# G32F002 register map
File version: 1.0
CPU: CM0PLUS r0p1, little endian, no MPU, no FPU, 4 interrupt priority bits
Registers are 32-bit, read-write, reset 0x0 unless marked. A register's access mark holds for its fields unless they carry their own. Offsets are from the block's base; [hi:lo] are bit positions; {n}, {i} and the like mark numbered series.

## ATMR — Advance timer
Base 0x40000000
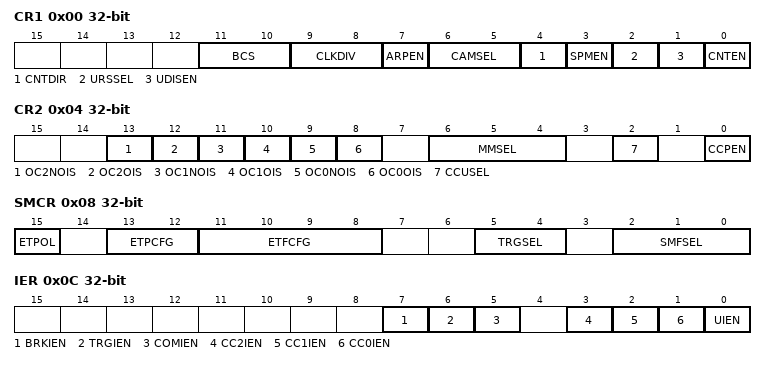
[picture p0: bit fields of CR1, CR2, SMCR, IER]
0x00 CR1 — control register 1
  [11:10] BCS — BRK Source Selection
  [9:8] CLKDIV — Clock division
  [7] ARPEN — Auto-reload preload enable
  [6:5] CAMSEL — Center-aligned mode selection
  [4] CNTDIR — Direction
  [3] SPMEN — One-pulse mode
  [2] URSSEL — Update request source
  [1] UDISEN — Update disable
  [0] CNTEN — Counter enable
0x04 CR2 — control register 2
  [13] OC2NOIS — Output Idle state 2
  [12] OC2OIS — Output Idle state 2
  [11] OC1NOIS — Output Idle state 1
  [10] OC1OIS — Output Idle state 1
  [9] OC0NOIS — Output Idle state 0
  [8] OC0OIS — Output Idle state 0
  [6:4] MMSEL — Master mode selection
  [2] CCUSEL — Capture/compare control update selection
  [0] CCPEN — Capture/compare preloaded control
0x08 SMCR — slave mode control register
  [15] ETPOL — External trigger polarity
  [13:12] ETPCFG — External trigger prescaler
  [11:8] ETFCFG — External trigger filter
  [5:4] TRGSEL — Trigger selection
  [2:0] SMFSEL — Slave mode selection
0x0C IER — Interrupt enable register
  [7] BRKIEN — Break interrupt enable
  [6] TRGIEN — Trigger interrupt enable
  [5] COMIEN — COM interrupt enable
  [3] CC2IEN — Capture/Compare 2 interrupt enable
  [2] CC1IEN — Capture/Compare 1 interrupt enable
  [1] CC0IEN — Capture/Compare 0 interrupt enable
  [0] UIEN — Update interrupt enable
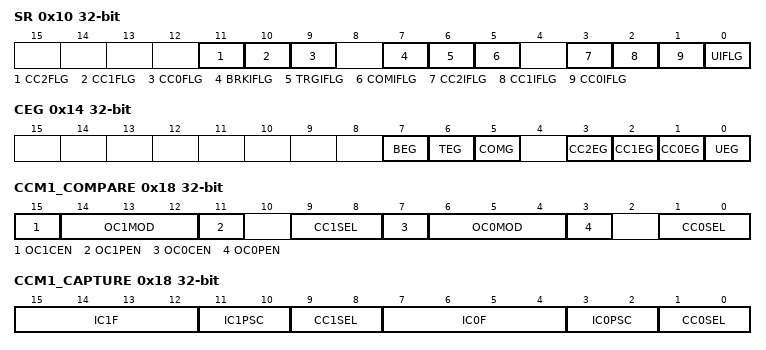
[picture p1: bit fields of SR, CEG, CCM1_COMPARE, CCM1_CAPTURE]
0x10 SR — status register
  [11] CC2FLG — Repeated capture/Compare 2 interrupt flag
  [10] CC1FLG — Repeated capture/Compare 1 interrupt flag
  [9] CC0FLG — Repeated capture/compare 0 interrupt flag
  [7] BRKIFLG — Break interrupt flag
  [6] TRGIFLG — Trigger interrupt flag
  [5] COMIFLG — COM interrupt flag
  [3] CC2IFLG — Capture/Compare 2 interrupt flag
  [2] CC1IFLG — Capture/Compare 1 interrupt flag
  [1] CC0IFLG — Capture/compare 0 interrupt flag
  [0] UIFLG — Update interrupt flag
0x14 CEG wo — event generation register
  [7] BEG — Break generation
  [6] TEG — Trigger generation
  [5] COMG — Capture/Compare control update generation
  [3] CC2EG — Capture/compare 2 generation
  [2] CC1EG — Capture/compare 1 generation
  [1] CC0EG — Capture/compare 0 generation
  [0] UEG — Update generation
0x18 CCM1_COMPARE — capture/compare mode register 1 (output mode)
  [15] OC1CEN — Output Compare 1 clear enable
  [14:12] OC1MOD — Output Compare 1 mode
  [11] OC1PEN — Output Compare 1 preload enable
  [9:8] CC1SEL — Capture/Compare 2 selection
  [7] OC0CEN — Output Compare 0 clear enable
  [6:4] OC0MOD — Output Compare 0 mode
  [3] OC0PEN — Output Compare 0 preload enable
  [1:0] CC0SEL — Capture/Compare 1 selection
0x18 CCM1_CAPTURE (alternate view of CCM1_COMPARE) — capture/compare mode register 1 (input mode)
  [15:12] IC1F — Input capture 2 filter
  [11:10] IC1PSC — Input capture 2 prescaler
  [9:8] CC1SEL — Capture/Compare 2 selection
  [7:4] IC0F — Input capture 1 filter
  [3:2] IC0PSC — Input capture 1 prescaler
  [1:0] CC0SEL — Capture/Compare 1 selection
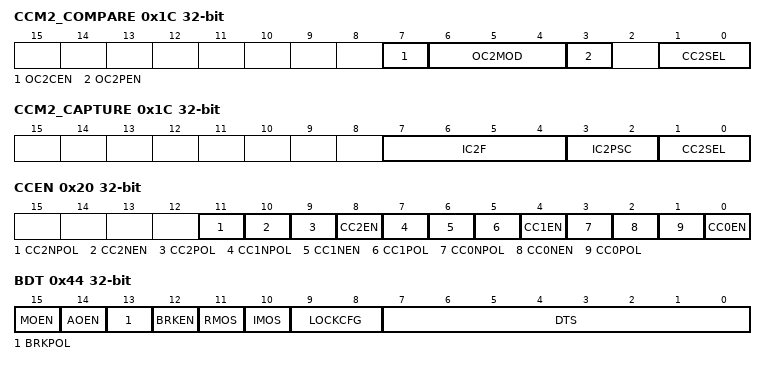
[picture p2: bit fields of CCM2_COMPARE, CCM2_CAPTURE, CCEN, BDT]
0x1C CCM2_COMPARE — capture/compare mode register 2 (output mode)
  [7] OC2CEN — Output compare 2 clear enable
  [6:4] OC2MOD — Output compare 2 mode
  [3] OC2PEN — Output compare 2 preload enable
  [1:0] CC2SEL — Capture/compare 2 selection
0x1C CCM2_CAPTURE (alternate view of CCM2_COMPARE) — capture/compare mode register 2 (input mode)
  [7:4] IC2F — Input capture 2 filter
  [3:2] IC2PSC — Input capture 2 prescaler
  [1:0] CC2SEL — Capture/compare 2 selection
0x20 CCEN — capture/compare enable register
  [11] CC2NPOL — Capture/Compare 2 output Polarity
  [10] CC2NEN — Capture/Compare 2 complementary output enable
  [9] CC2POL — Capture/Compare 2 output Polarity
  [8] CC2EN — Capture/Compare 2 output enable
  [7] CC1NPOL — Capture/Compare 1 output Polarity
  [6] CC1NEN — Capture/Compare 1 complementary output enable
  [5] CC1POL — Capture/Compare 1 output Polarity
  [4] CC1EN — Capture/Compare 1 output enable
  [3] CC0NPOL — Capture/Compare 0 output Polarity
  [2] CC0NEN — Capture/Compare 0 complementary output enable
  [1] CC0POL — Capture/Compare 0 output Polarity
  [0] CC0EN — Capture/Compare 0 output enable
0x24 CNT — counter
  [15:0] CNT — counter value
0x28 PSC — prescaler
  [15:0] PSC — Prescaler value
0x2C AUTORLD — auto-reload register
  [15:0] AUTORLD — Auto-reload value
0x30 REPCNT — repetition counter register
  [7:0] REPCNT — Repetition counter value
{0x34+4i} CC{i} (i=0..2) — capture/compare register {i}
  [15:0] CC{i} — Capture/Compare {i} value
0x44 BDT — break and dead-time register
  [15] MOEN — Main output enable
  [14] AOEN — Automatic output enable
  [13] BRKPOL — Break polarity
  [12] BRKEN — Break enable
  [11] RMOS — Off-state selection for Run mode
  [10] IMOS — Off-state selection for Idle mode
  [9:8] LOCKCFG — Lock configuration
  [7:0] DTS — Dead-time generator setup
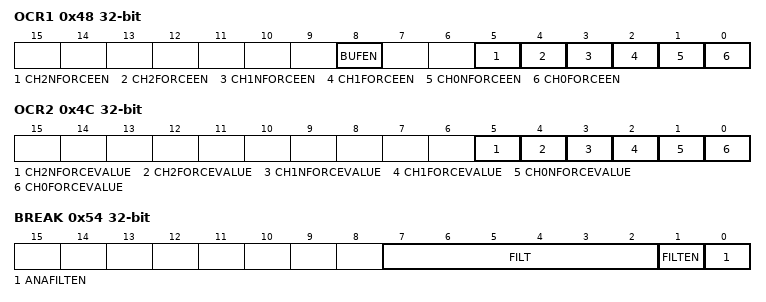
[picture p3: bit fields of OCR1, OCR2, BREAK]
0x48 OCR1 — Output ctrl register 1
  [8] BUFEN — Output Control Buffering is Enable
  [5] CH2NFORCEEN — Complementary Channel Output Control Enable for Channel 2
  [4] CH2FORCEEN — Outputs the Control Enable for Channel 2
  [3] CH1NFORCEEN — Complementary Channel Output Control Enable for Channel 1
  [2] CH1FORCEEN — Outputs the Control Enable for Channel 1
  [1] CH0NFORCEEN — Complementary Channel Output Control Enable for Channel 0
  [0] CH0FORCEEN — Outputs the Control Enable for Channel 0
0x4C OCR2 — Output ctrl register 2
  [5] CH2NFORCEVALUE — Complementary Channel Output Level for Channel 2
  [4] CH2FORCEVALUE — Outputs the Level for Channel 2
  [3] CH1NFORCEVALUE — Complementary Channel Output Level for Channel 1
  [2] CH1FORCEVALUE — Outputs the Level for Channel 1
  [1] CH0NFORCEVALUE — Complementary Channel Output Level for Channel 0
  [0] CH0FORCEVALUE — Outputs the Level for Channel 0
0x54 BREAK — BREAK Filter register
  [7:2] FILT — Filter coefficient
  [1] FILTEN — Break_in Fliter Enable
  [0] ANAFILTEN — Analog Break_in Fliter Enable
